VERSION ""

NS_ :

BS_:

BU_: XXX

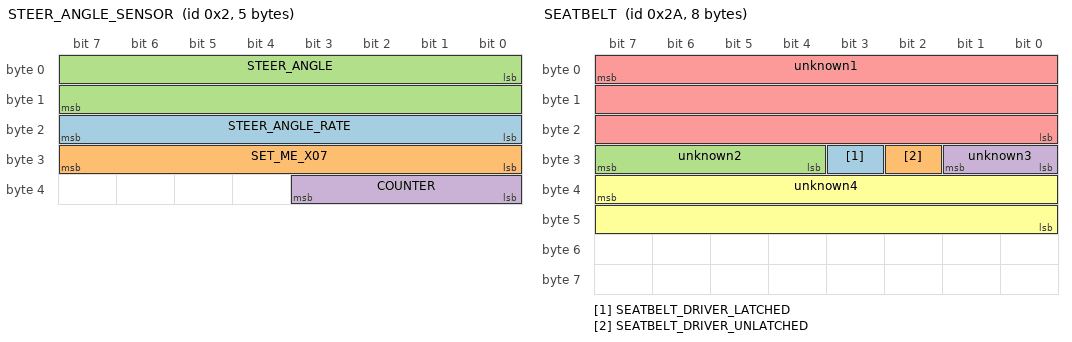
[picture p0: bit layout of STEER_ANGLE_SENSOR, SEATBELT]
BO_ 2 STEER_ANGLE_SENSOR: 5 XXX
 SG_ STEER_ANGLE_RATE : 16|8@1+ (1,0) [0|255] "" XXX
 SG_ SET_ME_X07 : 24|8@1+ (1,0) [0|255] "" XXX
 SG_ STEER_ANGLE : 0|16@1- (-0.1,0) [0|65535] "" XXX
 SG_ COUNTER : 32|4@1+ (1,0) [0|15] "" XXX

BO_ 42 SEATBELT: 8 XXX
 SG_ SEATBELT_DRIVER_LATCHED : 27|1@1+ (1,0) [0|3] "" XXX
 SG_ SEATBELT_DRIVER_UNLATCHED : 26|1@0+ (1,0) [0|1] "" XXX
 SG_ unknown2 : 31|4@0+ (1,0) [0|15] "" XXX
 SG_ unknown3 : 24|2@1+ (1,0) [0|3] "" XXX
 SG_ unknown1 : 7|24@0+ (1,0) [0|16777215] "" XXX
 SG_ unknown4 : 39|16@0+ (1,0) [0|65535] "" XXX

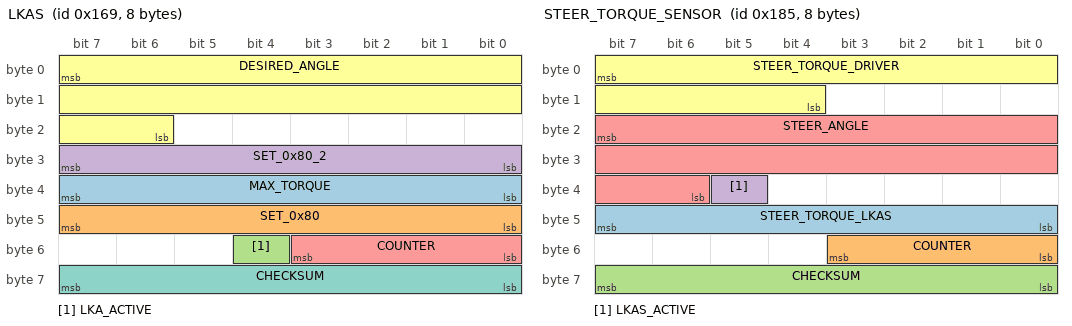
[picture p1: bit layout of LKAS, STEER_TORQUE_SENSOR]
BO_ 361 LKAS: 8 XXX
 SG_ MAX_TORQUE : 39|8@0+ (0.01,0) [0|255] "Nm" XXX
 SG_ SET_0x80 : 47|8@0+ (1,0) [0|255] "" XXX
 SG_ LKA_ACTIVE : 52|1@0+ (1,0) [0|15] "" XXX
 SG_ SET_0x80_2 : 31|8@0+ (1,0) [0|255] "" XXX
 SG_ COUNTER : 51|4@0+ (1,0) [0|15] "" XXX
 SG_ DESIRED_ANGLE : 7|18@0+ (-0.01,1310) [0|255] "" XXX
 SG_ CHECKSUM : 63|8@0+ (1,0) [0|255] "" XXX

BO_ 389 STEER_TORQUE_SENSOR: 8 XXX
 SG_ STEER_TORQUE_LKAS : 47|8@0+ (1,0) [0|255] "" XXX
 SG_ COUNTER : 51|4@0+ (1,0) [0|15] "" XXX
 SG_ CHECKSUM : 63|8@0+ (1,0) [0|127] "" XXX
 SG_ LKAS_ACTIVE : 37|1@0+ (1,0) [0|3] "" XXX
 SG_ STEER_ANGLE : 23|18@0+ (-0.01,1310) [0|262143] "" XXX
 SG_ STEER_TORQUE_DRIVER : 7|12@0+ (-0.01,20.47) [0|4095] "Nm" XXX

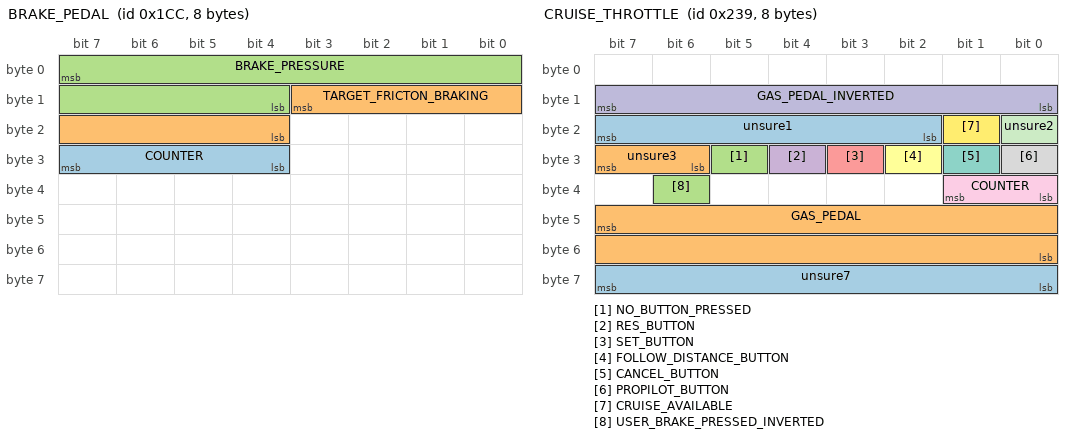
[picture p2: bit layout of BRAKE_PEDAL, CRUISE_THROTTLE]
BO_ 460 BRAKE_PEDAL: 8 XXX
 SG_ COUNTER : 31|4@0+ (1,0) [0|15] "" XXX
 SG_ TARGET_FRICTON_BRAKING : 11|8@0+ (1,0) [0|3] "" XXX
 SG_ BRAKE_PRESSURE : 7|12@0+ (1,0) [0|256] "" XXX

BO_ 569 CRUISE_THROTTLE: 8 XXX
 SG_ unsure1 : 23|6@0+ (1,0) [0|63] "" XXX
 SG_ unsure3 : 31|2@0+ (1,0) [0|3] "" XXX
 SG_ NO_BUTTON_PRESSED : 29|1@0+ (1,0) [0|1] "" XXX
 SG_ RES_BUTTON : 28|1@0+ (1,0) [0|1] "" XXX
 SG_ SET_BUTTON : 27|1@0+ (1,0) [0|1] "" XXX
 SG_ FOLLOW_DISTANCE_BUTTON : 26|1@0+ (1,0) [0|1] "" XXX
 SG_ CANCEL_BUTTON : 25|1@0+ (1,0) [0|1] "" XXX
 SG_ PROPILOT_BUTTON : 24|1@0+ (1,0) [0|1] "" XXX
 SG_ COUNTER : 32|2@1+ (1,0) [0|3] "" XXX
 SG_ GAS_PEDAL_INVERTED : 15|8@0+ (1,0) [0|255] "" XXX
 SG_ unsure2 : 16|1@0+ (1,0) [0|1] "" XXX
 SG_ CRUISE_AVAILABLE : 17|1@0+ (1,0) [0|1] "" XXX
 SG_ unsure7 : 63|8@0+ (1,0) [0|255] "" XXX
 SG_ GAS_PEDAL : 47|16@0+ (1,0) [0|65535] "" XXX
 SG_ USER_BRAKE_PRESSED_INVERTED : 38|1@0+ (1,0) [0|3] "" XXX

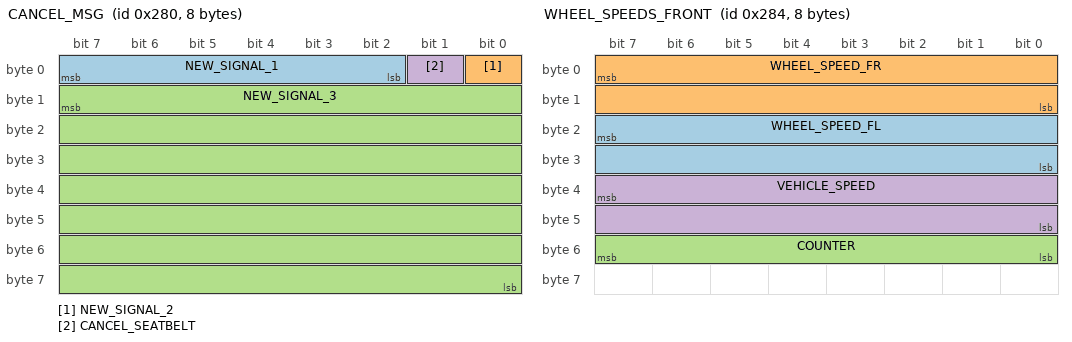
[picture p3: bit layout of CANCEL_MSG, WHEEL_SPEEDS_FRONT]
BO_ 640 CANCEL_MSG: 8 XXX
 SG_ NEW_SIGNAL_1 : 7|6@0+ (1,0) [0|63] "" XXX
 SG_ NEW_SIGNAL_2 : 0|1@0+ (1,0) [0|1] "" XXX
 SG_ NEW_SIGNAL_3 : 15|56@0+ (1,0) [0|72057594037927940] "" XXX
 SG_ CANCEL_SEATBELT : 1|1@0+ (1,0) [0|1] "" XXX

BO_ 644 WHEEL_SPEEDS_FRONT: 8 XXX
 SG_ WHEEL_SPEED_FL : 23|16@0+ (0.005,0) [0|65535] "KPH" XXX
 SG_ WHEEL_SPEED_FR : 7|16@0+ (0.005,0) [0|65535] "KPH" XXX
 SG_ COUNTER : 55|8@0+ (1,0) [0|255] "" XXX
 SG_ VEHICLE_SPEED : 39|16@0+ (0.0103813559,0) [0|65535] "" XXX

BO_ 645 WHEEL_SPEEDS_REAR: 8 XXX
 SG_ WHEEL_SPEED_RR : 7|16@0+ (0.005,0) [0|65535] "KPH" XXX
 SG_ WHEEL_SPEED_RL : 23|16@0+ (0.005,0) [0|65535] "KPH" XXX

BO_ 689 PROPILOT_HUD: 8 XXX
 SG_ LARGE_WARNING_FLASHING : 9|1@0+ (1,0) [0|1] "" XXX
 SG_ SIDE_RADAR_ERROR_FLASHING1 : 10|1@0+ (1,0) [0|1] "" XXX
 SG_ SIDE_RADAR_ERROR_FLASHING2 : 11|1@0+ (1,0) [0|1] "" XXX
 SG_ RIGHT_LANE_YELLOW_FLASH : 12|1@0+ (1,0) [0|1] "" XXX
 SG_ LEFT_LANE_YELLOW_FLASH : 13|1@0+ (1,0) [0|1] "" XXX
 SG_ LEAD_CAR : 14|1@0+ (1,0) [0|1] "" XXX
 SG_ LEAD_CAR_ERROR : 15|1@0+ (1,0) [0|1] "" XXX
 SG_ FRONT_RADAR_ERROR : 16|1@0+ (1,0) [0|1] "" XXX
 SG_ FRONT_RADAR_ERROR_FLASHING : 17|1@0+ (1,0) [0|1] "" XXX
 SG_ RIGHT_LANE_GREEN : 24|1@0+ (1,0) [0|1] "" XXX
 SG_ LEFT_LANE_GREEN : 25|1@0+ (1,0) [0|1] "" XXX
 SG_ SIDE_RADAR_ERROR_FLASHING3 : 27|1@0+ (1,0) [0|1] "" XXX
 SG_ LKAS_ERROR_FLASHING : 29|1@0+ (1,0) [0|1] "" XXX
 SG_ SAFETY_SHIELD_ACTIVE : 44|1@0+ (1,0) [0|1] "" XXX
 SG_ LARGE_STEERING_WHEEL_ICON : 61|2@0+ (1,0) [0|3] "" XXX
 SG_ RIGHT_LANE_GREEN_FLASH : 62|1@0+ (1,0) [0|1] "" XXX
 SG_ LEFT_LANE_GREEN_FLASH : 63|1@0+ (1,0) [0|1] "" XXX
 SG_ FOLLOW_DISTANCE : 3|2@0+ (1,0) [0|3] "" XXX
 SG_ AUDIBLE_TONE : 47|3@0+ (1,0) [0|8] "" XXX
 SG_ SPEED_SET_ICON : 7|2@0+ (1,0) [0|3] "" XXX
 SG_ SMALL_STEERING_WHEEL_ICON : 42|3@0+ (1,0) [0|7] "" XXX
 SG_ SET_SPEED : 39|8@0+ (1,0) [0|255] "" XXX
 SG_ unknown02 : 1|2@0+ (1,0) [0|3] "" XXX
 SG_ unknown05 : 5|2@0+ (1,0) [0|3] "" XXX
 SG_ unknown08 : 8|7@0+ (1,0) [0|63] "" XXX
 SG_ unknown26 : 26|1@0+ (1,0) [0|1] "" XXX
 SG_ unknown28 : 28|1@0+ (1,0) [0|1] "" XXX
 SG_ unknown31 : 31|2@0+ (1,0) [0|3] "" XXX
 SG_ unknown43 : 43|1@0+ (1,0) [0|1] "" XXX
 SG_ unknown55 : 55|8@0+ (1,0) [0|63] "" XXX
 SG_ unknown59 : 59|4@0+ (1,0) [0|15] "" XXX

BO_ 783 CRUISE_STATE: 3 XXX
 SG_ CRUISE_ENABLED : 3|1@0+ (1,0) [0|1] "" XXX

BO_ 852 ESP: 8 XXX
 SG_ ESP_DISABLED : 38|1@0+ (1,0) [0|1] "" XXX
 SG_ VEHICLE_SPEED : 7|16@0+ (1,0) [0|65535] "" XXX

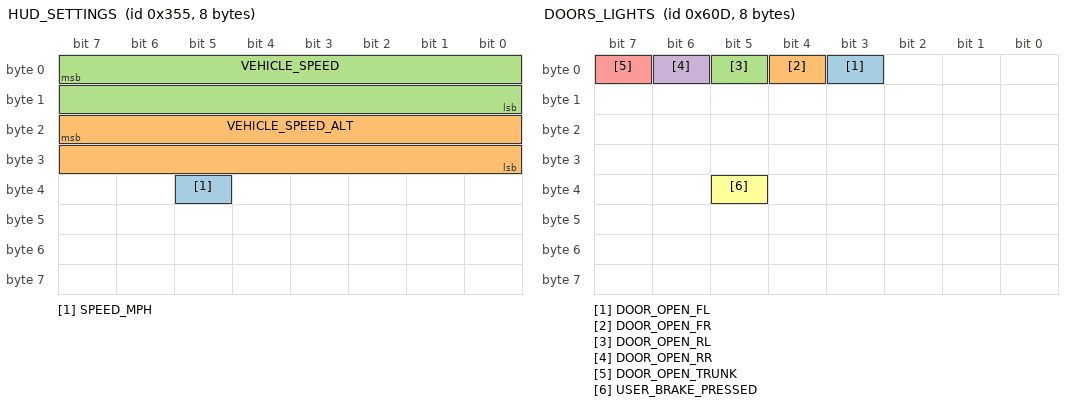
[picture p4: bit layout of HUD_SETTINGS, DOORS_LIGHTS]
BO_ 853 HUD_SETTINGS: 8 XXX
 SG_ SPEED_MPH : 37|1@0+ (1,0) [0|1] "" XXX
 SG_ VEHICLE_SPEED_ALT : 23|16@0+ (1,0) [0|65535] "" XXX
 SG_ VEHICLE_SPEED : 7|16@0+ (1,0) [0|65535] "" XXX

BO_ 856 LIGHTS: 8 XXX
 SG_ LEFT_BLINKER : 17|1@0+ (1,0) [0|1] "" XXX
 SG_ RIGHT_BLINKER : 18|1@0+ (1,0) [0|1] "" XXX

BO_ 1057 GEARBOX: 3 XXX
 SG_ GEAR_SHIFTER : 5|3@0+ (1,0) [0|255] "" XXX

BO_ 1228 PROPILOT_HUD_INFO_MSG: 8 XXX
 SG_ NA_HIGH_ACCEL_TEMP : 0|1@0+ (1,0) [0|1] "" XXX
 SG_ SIDE_RADAR_NA_HIGH_CABIN_TEMP : 8|1@0+ (1,0) [0|1] "" XXX
 SG_ SIDE_RADAR_MALFUNCTION : 11|1@0+ (1,0) [0|1] "" XXX
 SG_ LKAS_MALFUNCTION : 12|1@0+ (1,0) [0|1] "" XXX
 SG_ FRONT_RADAR_MALFUNCTION : 13|1@0+ (1,0) [0|1] "" XXX
 SG_ SIDE_RADAR_NA_CLEAN_REAR_CAMERA : 14|1@0+ (1,0) [0|1] "" XXX
 SG_ NA_POOR_ROAD_CONDITIONS : 16|1@0+ (1,0) [0|1] "" XXX
 SG_ CURRENTLY_UNAVAILABLE : 17|1@0+ (1,0) [0|1] "" XXX
 SG_ SAFETY_SHIELD_OFF : 18|1@0+ (1,0) [0|1] "" XXX
 SG_ FRONT_COLLISION_NA_FRONT_RADAR_OBSTRUCTION : 20|1@0+ (1,0) [0|1] "" XXX
 SG_ PEDAL_MISSAPPLICATION_SYSTEM_ACTIVATED : 24|1@0+ (1,0) [0|1] "" XXX
 SG_ SIDE_IMPACT_NA_RADAR_OBSTRUCTION : 25|1@0+ (1,0) [0|1] "" XXX
 SG_ WARNING_DO_NOT_ENTER : 33|1@0+ (1,0) [0|1] "" XXX
 SG_ SIDE_IMPACT_SYSTEM_OFF : 34|1@0+ (1,0) [0|1] "" XXX
 SG_ SIDE_IMPACT_MALFUNCTION : 35|1@0+ (1,0) [0|1] "" XXX
 SG_ FRONT_COLLISION_MALFUNCTION : 36|1@0+ (1,0) [0|1] "" XXX
 SG_ SIDE_RADAR_MALFUNCTION2 : 37|1@0+ (1,0) [0|1] "" XXX
 SG_ LKAS_MALFUNCTION2 : 38|1@0+ (1,0) [0|1] "" XXX
 SG_ FRONT_RADAR_MALFUNCTION2 : 39|1@0+ (1,0) [0|1] "" XXX
 SG_ PROPILOT_NA_MSGS : 42|3@0+ (1,0) [0|7] "" XXX
 SG_ BOTTOM_MSG : 45|3@0+ (1,0) [0|7] "" XXX
 SG_ HANDS_ON_WHEEL_WARNING : 47|1@0+ (1,0) [0|1] "" XXX
 SG_ WARNING_STEP_ON_BRAKE_NOW : 51|1@0+ (1,0) [0|1] "" XXX
 SG_ PROPILOT_NA_FRONT_CAMERA_OBSTRUCTED : 52|1@0+ (1,0) [0|1] "" XXX
 SG_ PROPILOT_NA_HIGH_CABIN_TEMP : 53|1@0+ (1,0) [0|1] "" XXX
 SG_ WARNING_PROPILOT_MALFUNCTION : 54|1@0+ (1,0) [0|3] "" XXX
 SG_ ACC_UNAVAILABLE_HIGH_CABIN_TEMP : 62|1@0+ (1,0) [0|1] "" XXX
 SG_ ACC_NA_FRONT_CAMERA_IMPARED : 63|1@0+ (1,0) [0|1] "" XXX
 SG_ unknown07 : 7|7@0+ (1,0) [0|127] "" XXX
 SG_ unknown10 : 10|2@0+ (1,0) [0|3] "" XXX
 SG_ unknown15 : 15|1@0+ (1,0) [0|1] "" XXX
 SG_ unknown23 : 23|3@0+ (1,0) [0|7] "" XXX
 SG_ unknown19 : 19|1@0+ (1,0) [0|1] "" XXX
 SG_ unknown31 : 31|6@0+ (1,0) [0|63] "" XXX
 SG_ unknown32 : 32|1@0+ (1,0) [0|1] "" XXX
 SG_ unknown46 : 46|1@0+ (1,0) [0|1] "" XXX
 SG_ unknown50 : 50|3@0+ (1,0) [0|7] "" XXX
 SG_ unknown55 : 55|1@0+ (1,0) [0|1] "" XXX
 SG_ unknown61 : 61|6@0+ (1,0) [0|63] "" XXX

BO_ 1549 DOORS_LIGHTS: 8 XXX
 SG_ DOOR_OPEN_FL : 3|1@0+ (1,0) [0|1] "" XXX
 SG_ DOOR_OPEN_FR : 4|1@0+ (1,0) [0|1] "" XXX
 SG_ DOOR_OPEN_RL : 5|1@0+ (1,0) [0|1] "" XXX
 SG_ DOOR_OPEN_RR : 6|1@0+ (1,0) [0|1] "" XXX
 SG_ DOOR_OPEN_TRUNK : 7|1@0+ (1,0) [0|1] "" XXX
 SG_ USER_BRAKE_PRESSED : 37|1@0+ (1,0) [0|3] "" XXX

BO_ 1227 LKAS_SETTINGS: 8 XXX
 SG_ LKAS_ENABLED : 51|1@0+ (1,0) [0|1] "" XXX

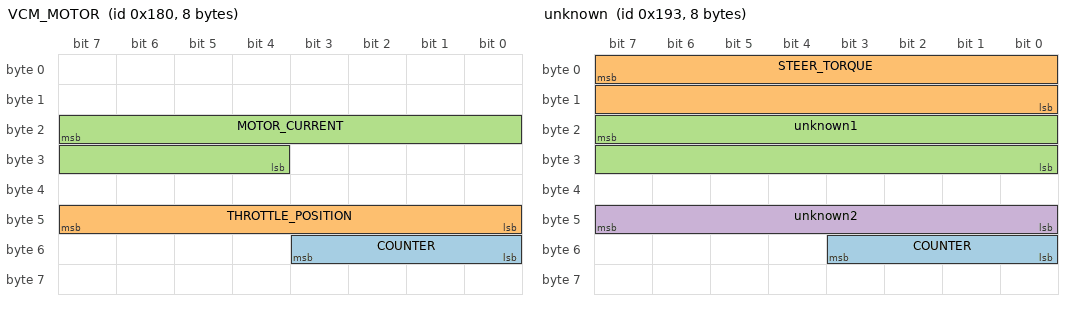
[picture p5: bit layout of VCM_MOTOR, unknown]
BO_ 384 VCM_MOTOR: 8 XXX
 SG_ COUNTER : 48|4@1+ (1,0) [0|15] "" XXX
 SG_ THROTTLE_POSITION : 47|8@0+ (1,0) [0|255] "" XXX
 SG_ MOTOR_CURRENT : 23|12@0- (1,0) [0|4095] "" XXX

BO_ 372 SHIFTER_STATUS_RELAY_FROM_EVCAN: 8 XXX
 SG_ COUNTER : 39|8@0+ (1,0) [0|255] "" XXX
 SG_ SHIFTER_POSITION : 31|8@0+ (1,0) [0|255] "" XXX

BO_ 403 unknown: 8 XXX
 SG_ COUNTER : 48|4@1+ (1,0) [0|15] "" XXX
 SG_ STEER_TORQUE : 7|16@0+ (1,0) [0|65535] "" XXX
 SG_ unknown1 : 23|16@0- (1,0) [0|65535] "" XXX
 SG_ unknown2 : 47|8@0- (1,0) [0|255] "" XXX

BO_ 459 BCM_BRAKE_STATUS: 8 XXX
 SG_ TARGET_REGEN_BRAKING : 7|12@0+ (1,0) [0|4095] "" XXX
 SG_ TARGET_TOTAL_BRAKING : 23|12@0+ (1,0) [0|4095] "" XXX

BO_ 658 unknown: 8 XXX
 SG_ 12V_BATTERY_VOLTAGE : 31|8@0+ (0.1,0) [0|255] "V" XXX
 SG_ FRICTION_BRAKING_FORCE : 55|8@0+ (1,0) [0|255] "" XXX

BO_ 264 COUNTER_CHARGEPORT_OPEN: 8 XXX
 SG_ counter0 : 8|4@1+ (1,0) [0|15] "" XXX
 SG_ CHECKSUM : 23|8@0+ (1,0) [0|255] "" XXX

BO_ 470 unknown: 8 XXX
 SG_ NEW_SIGNAL_2 : 23|16@0+ (1,0) [0|65535] "" XXX
 SG_ NEW_SIGNAL_3 : 35|1@0+ (1,0) [0|1] "" XXX
 SG_ NEW_SIGNAL_6 : 47|8@0+ (1,0) [0|255] "" XXX
 SG_ TARGET_BRAKING_INVERTERED : 7|16@0+ (1,0) [0|65535] "" XXX

BO_ 451 unknown_counter: 8 XXX
 SG_ counter0 : 40|2@1+ (1,0) [0|3] "" XXX
 SG_ CHECKSUM : 63|8@0+ (1,0) [0|255] "" XXX

BO_ 688 NEW_MSG_2: 8 XXX
 SG_ NEW_SIGNAL_3 : 23|8@0+ (1,0) [0|255] "" XXX
 SG_ NEW_SIGNAL_1 : 7|8@0+ (1,0) [0|255] "" XXX
 SG_ NEW_SIGNAL_2 : 15|8@0+ (1,0) [0|255] "" XXX
 SG_ COUNTER : 55|4@0+ (1,0) [0|255] "" XXX
 SG_ BRAKE_LIGHT_ON : 30|1@0+ (1,0) [0|3] "" XXX

BO_ 581 COUNTER_CHARGEPORT_OPEN: 8 XXX
 SG_ counter0 : 39|8@0+ (1,0) [0|255] "" XXX
 SG_ CHECKSUM : 63|8@0+ (1,0) [0|255] "" XXX

BO_ 634 NEW_MSG_4: 8 XXX
 SG_ COUNTER : 40|4@1+ (1,0) [0|15] "" XXX
 SG_ unknown2 : 25|1@0+ (1,0) [0|1] "" XXX
 SG_ unknown1 : 29|1@0+ (1,0) [0|1] "" XXX
 SG_ SPEED : 7|16@0+ (1,0) [0|65535] "" XXX

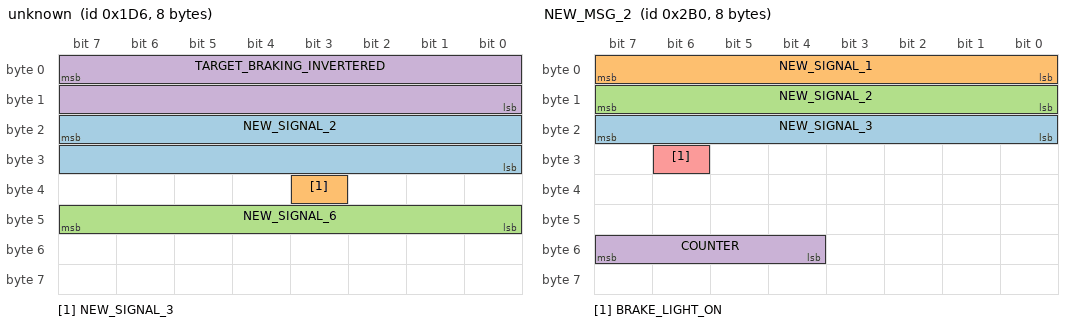
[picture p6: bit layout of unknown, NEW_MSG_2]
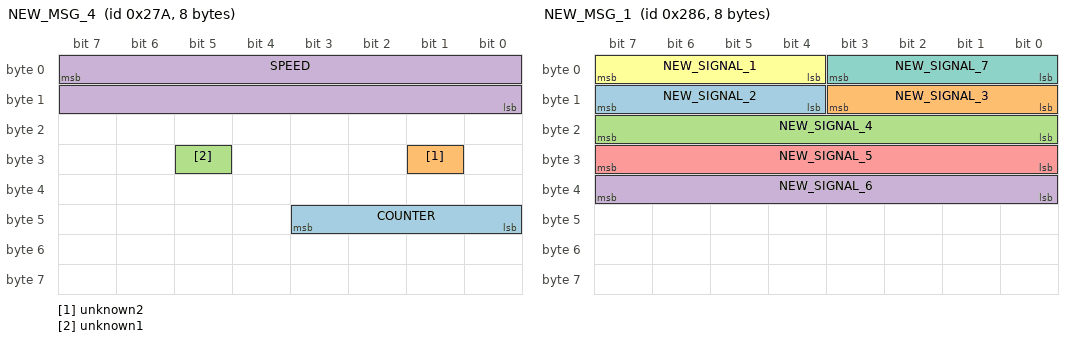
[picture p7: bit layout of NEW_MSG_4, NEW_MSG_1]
BO_ 520 unknown: 8 XXX

BO_ 646 NEW_MSG_1: 8 XXX
 SG_ NEW_SIGNAL_2 : 15|4@0+ (1,0) [0|15] "" XXX
 SG_ NEW_SIGNAL_3 : 8|4@1+ (1,0) [0|15] "" XXX
 SG_ NEW_SIGNAL_4 : 23|8@0+ (1,0) [0|255] "" XXX
 SG_ NEW_SIGNAL_6 : 39|8@0+ (1,0) [0|255] "" XXX
 SG_ NEW_SIGNAL_5 : 31|8@0+ (1,0) [0|255] "" XXX
 SG_ NEW_SIGNAL_1 : 7|4@0+ (1,0) [0|15] "" XXX
 SG_ NEW_SIGNAL_7 : 0|4@1+ (1,0) [0|15] "" XXX

BO_ 682 NEW_MSG_3: 8 XXX
 SG_ NEW_SIGNAL_1 : 15|8@0+ (1,0) [0|255] "" XXX

BO_ 1459 NEW_MSG_5: 8 XXX
 SG_ HV_BATT_TEMP : 7|8@0+ (0.25,0) [0|255] "C" XXX
 SG_ HV_BATT_GIDS : 39|16@0+ (1,0) [0|65535] "" XXX

BO_ 1354 VCM_RELAY_AC: 8 XXX
 SG_ AMBIENT_TEMP : 63|8@0+ (1,-41) [0|255] "F" XXX

BO_ 861 NEW_MSG_6: 8 XXX
 SG_ BRAKE_LIGHT_ON : 36|1@0+ (1,0) [0|1] "" XXX

CM_ SG_ 372 SHIFTER_POSITION "AA=P/N, BB=D, 99=R";
CM_ SG_ 264 counter0 "4-bit counter, only when charge port door is open.";
CM_ SG_ 581 counter0 "8-bit counter, counts only when charge port door is open";
VAL_ 689 LARGE_STEERING_WHEEL_ICON 0 "NO_STEERINGWHEEL" 1 "GRAY_STEERINGWHEEL" 2 "GREEN_STEERINGWHEEL" 3 "GREEN_STEERINGWHEEL_FLASHING" ;
VAL_ 689 FOLLOW_DISTANCE 0 "NO_FOLLOW_DISTANCE" 1 "FOLLOW_DISTANCE_1" 2 "FOLLOW_DISTANCE_2" 3 "FOLLOW_DISANCE_3" ;
VAL_ 689 AUDIBLE_TONE 0 "NO_TONE" 1 "CONT" 2 "FAST_BEEP_CONT" 3 "TRIPLE_FAST_BEEP_CONT" 4 "SLOW_BEEP_CONT" 5 "QUAD_SLOW_BEEP_CONT" 6 "SINGLE_BEEP_ONCE" 7 "DOUBLE_BEEP_ONCE" ;
VAL_ 689 SMALL_STEERING_WHEEL_ICON 0 "NO_ICON" 1 "GRAY_ICON" 2 "GRAY_ICON_FLASHING" 3 "GREEN_ICON" 4 "GREEN_ICON_FLASHING" 5 "RED_ICON" 6 "RED_ICON_FLASHING" 7 "YELLOW_ICON" ;
VAL_ 1057 GEAR_SHIFTER 7 "B" 4 "D" 3 "N" 2 "R" 1 "P" ;
VAL_ 1228 PROPILOT_NA_MSGS 0 "NO_MSG" 1 "NA_FRONT_CAMERA_IMPARED" 2 "STEERING_ASSIST_ON_STANDBY" 3 "NA_PARKING_ASSIST_ENABLED" 4 "STEER_ASSIST_CURRENTLY_NA" 5 "NA_BAD_WEATHER" 6 "NA_PARK_BRAKE_ON" 7 "NA_SEATBELT_NOT_FASTENED" ;
VAL_ 1228 BOTTOM_MSG 0 "OK_STEER_ASSIST_SETTINGS" 1 "NO_MSG" 2 "PRESS_SET_TO_SET_SPEED" 3 "PRESS_RES_SET_TO_CHANGE_SPEED" 4 "PRESS_RES_TO_RESTART" 5 "NO_MSG" 6 "CRUISE_NOT_AVAIL" 7 "NO_MSG" ;
